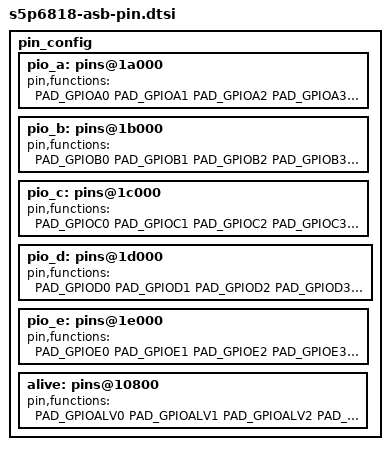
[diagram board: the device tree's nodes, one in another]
/*
 * s5p6818 plls
 *
 * Copyright 2009 Nexell Co.
 *		http://www.nexell.co.kr
 *
 * Licensed under GPLv2 or later.
 */


#include "../../../../../include/nexell/target/s5p6818_asb_gpio.h"

		pin_config {
          	pio_a:pins@1a000 {
	        	pin,functions = <
	        		PAD_GPIOA0  PAD_GPIOA1  PAD_GPIOA2  PAD_GPIOA3  PAD_GPIOA4  PAD_GPIOA5  PAD_GPIOA6  PAD_GPIOA7  PAD_GPIOA8  PAD_GPIOA9
					PAD_GPIOA10 PAD_GPIOA11 PAD_GPIOA12 PAD_GPIOA13 PAD_GPIOA14 PAD_GPIOA15 PAD_GPIOA16 PAD_GPIOA17 PAD_GPIOA18 PAD_GPIOA19
					PAD_GPIOA20 PAD_GPIOA21 PAD_GPIOA22 PAD_GPIOA23 PAD_GPIOA24 PAD_GPIOA25 PAD_GPIOA26 PAD_GPIOA27 PAD_GPIOA28 PAD_GPIOA29
					PAD_GPIOA30 PAD_GPIOA31
	        		>;
	        };
	        pio_b:pins@1b000 {
	        	pin,functions = <
	        		PAD_GPIOB0  PAD_GPIOB1  PAD_GPIOB2  PAD_GPIOB3  PAD_GPIOB4  PAD_GPIOB5  PAD_GPIOB6  PAD_GPIOB7  PAD_GPIOB8  PAD_GPIOB9
					PAD_GPIOB10 PAD_GPIOB11 PAD_GPIOB12 PAD_GPIOB13 PAD_GPIOB14 PAD_GPIOB15 PAD_GPIOB16 PAD_GPIOB17 PAD_GPIOB18 PAD_GPIOB19
					PAD_GPIOB20 PAD_GPIOB21 PAD_GPIOB22 PAD_GPIOB23 PAD_GPIOB24 PAD_GPIOB25 PAD_GPIOB26 PAD_GPIOB27 PAD_GPIOB28 PAD_GPIOB29
					PAD_GPIOB30 PAD_GPIOB31
	        		>;
	        };
	        pio_c:pins@1c000 {
	        	pin,functions = <
	        		PAD_GPIOC0  PAD_GPIOC1  PAD_GPIOC2  PAD_GPIOC3  PAD_GPIOC4  PAD_GPIOC5  PAD_GPIOC6  PAD_GPIOC7  PAD_GPIOC8  PAD_GPIOC9
					PAD_GPIOC10 PAD_GPIOC11 PAD_GPIOC12 PAD_GPIOC13 PAD_GPIOC14 PAD_GPIOC15 PAD_GPIOC16 PAD_GPIOC17 PAD_GPIOC18 PAD_GPIOC19
					PAD_GPIOC20 PAD_GPIOC21 PAD_GPIOC22 PAD_GPIOC23 PAD_GPIOC24 PAD_GPIOC25 PAD_GPIOC26 PAD_GPIOC27 PAD_GPIOC28 PAD_GPIOC29
					PAD_GPIOC30 PAD_GPIOC31
	        		>;
	        };
	        pio_d:pins@1d000 {
	        	pin,functions = <
	        		PAD_GPIOD0  PAD_GPIOD1  PAD_GPIOD2  PAD_GPIOD3  PAD_GPIOD4  PAD_GPIOD5  PAD_GPIOD6  PAD_GPIOD7  PAD_GPIOD8  PAD_GPIOD9
					PAD_GPIOD10 PAD_GPIOD11 PAD_GPIOD12 PAD_GPIOD13 PAD_GPIOD14 PAD_GPIOD15 PAD_GPIOD16 PAD_GPIOD17 PAD_GPIOD18 PAD_GPIOD19
					PAD_GPIOD20 PAD_GPIOD21 PAD_GPIOD22 PAD_GPIOD23 PAD_GPIOD24 PAD_GPIOD25 PAD_GPIOD26 PAD_GPIOD27 PAD_GPIOD28 PAD_GPIOD29
					PAD_GPIOD30 PAD_GPIOD31
	        		>;
	        };
	        pio_e:pins@1e000 {
	        	pin,functions = <
	        		PAD_GPIOE0  PAD_GPIOE1  PAD_GPIOE2  PAD_GPIOE3  PAD_GPIOE4  PAD_GPIOE5  PAD_GPIOE6  PAD_GPIOE7  PAD_GPIOE8  PAD_GPIOE9
					PAD_GPIOE10 PAD_GPIOE11 PAD_GPIOE12 PAD_GPIOE13 PAD_GPIOE14 PAD_GPIOE15 PAD_GPIOE16 PAD_GPIOE17 PAD_GPIOE18 PAD_GPIOE19
					PAD_GPIOE20 PAD_GPIOE21 PAD_GPIOE22 PAD_GPIOE23 PAD_GPIOE24 PAD_GPIOE25 PAD_GPIOE26 PAD_GPIOE27 PAD_GPIOE28 PAD_GPIOE29
					PAD_GPIOE30 PAD_GPIOE31
	        		>;
	        };
	        alive:pins@10800 {
	        	pin,functions = < PAD_GPIOALV0 PAD_GPIOALV1 PAD_GPIOALV2 PAD_GPIOALV3 PAD_GPIOALV4 PAD_GPIOALV5 >;
	        };
		};
